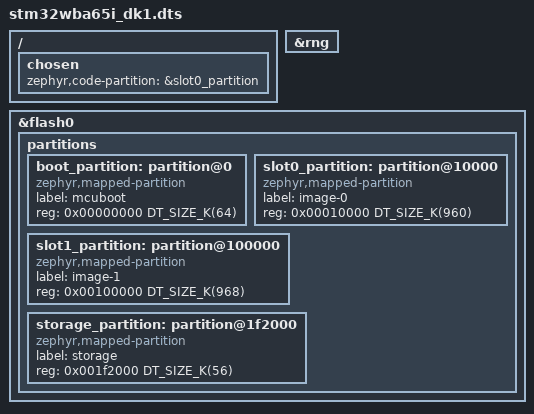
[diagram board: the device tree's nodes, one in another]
/*
 * Copyright (c) 2025 STMicroelectronics
 *
 * SPDX-License-Identifier: Apache-2.0
 */

/dts-v1/;
#include "stm32wba65i_dk1-common.dtsi"
#include <mem.h>

/ {
	chosen {
		zephyr,code-partition = &slot0_partition;
	};
};

&rng {
	status = "okay";
};

&flash0 {
	partitions {
		#address-cells = <1>;
		#size-cells = <1>;
		ranges;

		boot_partition: partition@0 {
			compatible = "zephyr,mapped-partition";
			label = "mcuboot";
			reg = <0x00000000 DT_SIZE_K(64)>;
		};

		slot0_partition: partition@10000 {
			compatible = "zephyr,mapped-partition";
			label = "image-0";
			reg = <0x00010000 DT_SIZE_K(960)>;
		};

		slot1_partition: partition@100000 {
			compatible = "zephyr,mapped-partition";
			label = "image-1";
			reg = <0x00100000 DT_SIZE_K(968)>;
		};

		storage_partition: partition@1f2000 {
			compatible = "zephyr,mapped-partition";
			label = "storage";
			reg = <0x001f2000 DT_SIZE_K(56)>;
		};
	};
};
